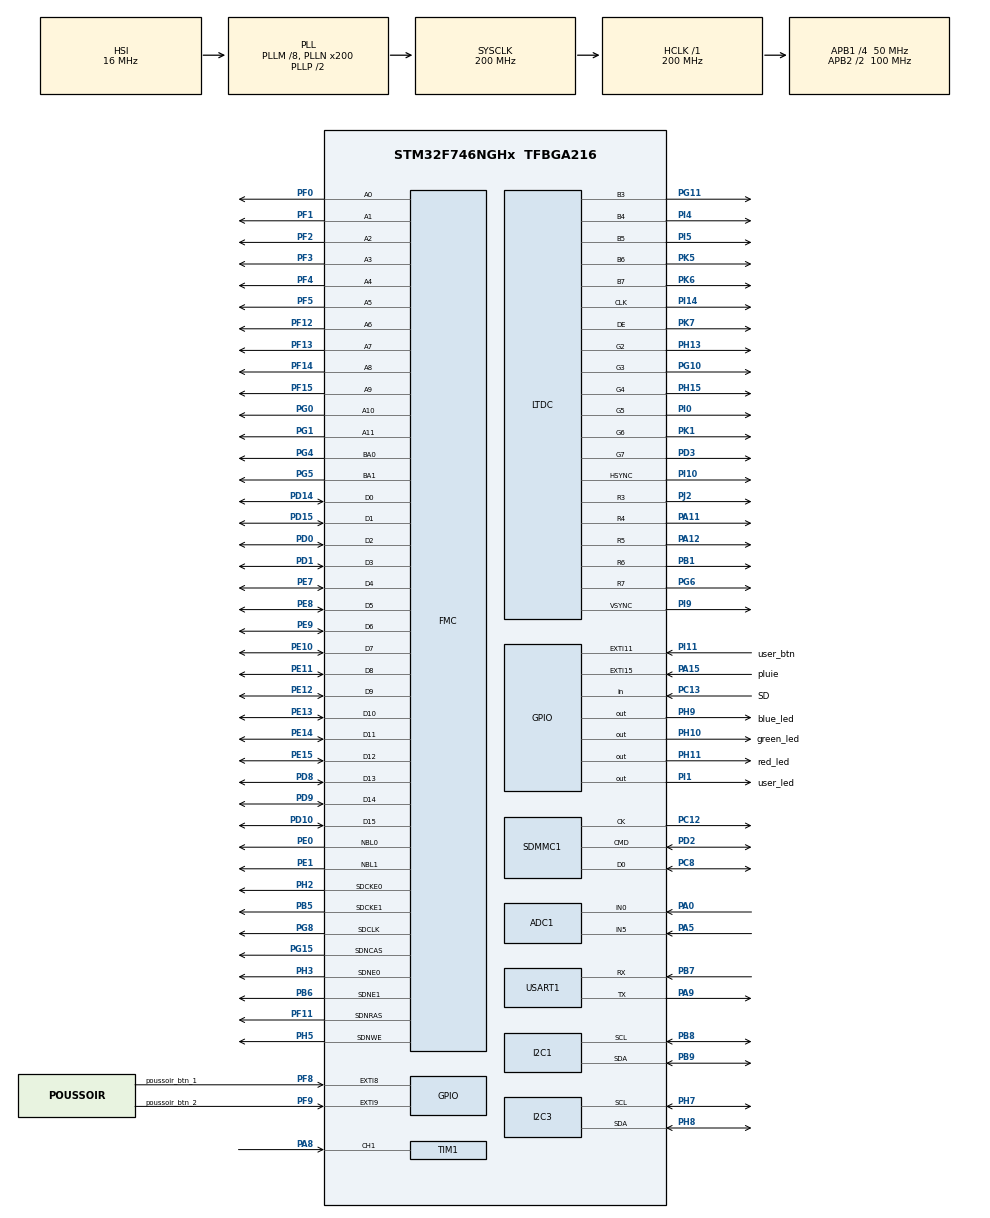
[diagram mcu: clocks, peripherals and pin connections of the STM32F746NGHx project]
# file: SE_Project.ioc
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ADC1.Channel-0\#ChannelRegularConversion=ADC_CHANNEL_5
ADC1.ContinuousConvMode=ENABLE
ADC1.NbrOfConversionFlag=1
ADC1.Rank-0\#ChannelRegularConversion=1
ADC1.SamplingTime-0\#ChannelRegularConversion=ADC_SAMPLETIME_3CYCLES
ADC1.master=1
ADC2.Channel-0\#ChannelRegularConversion=ADC_CHANNEL_0
ADC2.NbrOfConversionFlag=1
ADC2.Rank-0\#ChannelRegularConversion=1
ADC2.SamplingTime-0\#ChannelRegularConversion=ADC_SAMPLETIME_3CYCLES
Dma.Request0=SDMMC1_RX
Dma.Request1=SDMMC1_TX
Dma.SDMMC1_RX.0.Direction=DMA_PERIPH_TO_MEMORY
Dma.SDMMC1_RX.0.FIFOMode=DMA_FIFOMODE_ENABLE
Dma.SDMMC1_RX.0.FIFOThreshold=DMA_FIFO_THRESHOLD_FULL
Dma.SDMMC1_RX.0.Instance=DMA2_Stream3
Dma.SDMMC1_RX.0.MemBurst=DMA_MBURST_INC4
Dma.SDMMC1_RX.0.MemDataAlignment=DMA_MDATAALIGN_WORD
Dma.SDMMC1_RX.0.MemInc=DMA_MINC_ENABLE
Dma.SDMMC1_RX.0.Mode=DMA_PFCTRL
Dma.SDMMC1_RX.0.PeriphBurst=DMA_PBURST_INC4
Dma.SDMMC1_RX.0.PeriphDataAlignment=DMA_PDATAALIGN_WORD
Dma.SDMMC1_RX.0.PeriphInc=DMA_PINC_DISABLE
Dma.SDMMC1_RX.0.Priority=DMA_PRIORITY_LOW
Dma.SDMMC1_TX.1.Direction=DMA_MEMORY_TO_PERIPH
Dma.SDMMC1_TX.1.FIFOMode=DMA_FIFOMODE_ENABLE
Dma.SDMMC1_TX.1.FIFOThreshold=DMA_FIFO_THRESHOLD_FULL
Dma.SDMMC1_TX.1.Instance=DMA2_Stream6
Dma.SDMMC1_TX.1.MemBurst=DMA_MBURST_INC4
Dma.SDMMC1_TX.1.MemDataAlignment=DMA_MDATAALIGN_WORD
Dma.SDMMC1_TX.1.MemInc=DMA_MINC_ENABLE
Dma.SDMMC1_TX.1.Mode=DMA_PFCTRL
Dma.SDMMC1_TX.1.PeriphBurst=DMA_PBURST_INC4
Dma.SDMMC1_TX.1.PeriphDataAlignment=DMA_PDATAALIGN_WORD
Dma.SDMMC1_TX.1.PeriphInc=DMA_PINC_DISABLE
Dma.SDMMC1_TX.1.Priority=DMA_PRIORITY_LOW
FATFS.BSP.number=1
FATFS.USE_DMA_CODE_SD=1
FATFS0.BSP.STBoard=false
FATFS0.BSP.api=Unknown
FATFS0.BSP.instance=PC13
FATFS0.BSP.ip=GPIO
FATFS0.BSP.mode=Input
FATFS0.BSP.name=Detect_SDIO
FATFS0.BSP.solution=PC13
I2C1.Timing=0x00C0EAFF
I2C3.Timing=0x00C0EAFF
Mcu.Family=STM32F7
Mcu.Name=STM32F746NGHx
Mcu.Package=TFBGA216
NVIC.ADC_IRQn=true\:0\:0\:false\:false\:true\:true\:true\:true
NVIC.DMA2_Stream3_IRQn=true\:0\:0\:false\:false\:true\:false\:true\:true
NVIC.DMA2_Stream6_IRQn=true\:0\:0\:false\:false\:true\:false\:true\:true
NVIC.EXTI15_10_IRQn=true\:0\:0\:false\:false\:true\:true\:true\:true
NVIC.EXTI9_5_IRQn=true\:0\:0\:false\:false\:true\:true\:true\:true
NVIC.PVD_IRQn=true\:0\:0\:false\:false\:true\:true\:true\:true
NVIC.PriorityGroup=NVIC_PRIORITYGROUP_4
NVIC.RCC_IRQn=true\:0\:0\:false\:false\:true\:true\:false\:true
NVIC.SDMMC1_IRQn=true\:0\:0\:false\:false\:true\:true\:true\:true
NVIC.TIM1_CC_IRQn=true\:0\:0\:false\:false\:true\:true\:true\:true
NVIC.TIM2_IRQn=true\:0\:0\:false\:false\:true\:true\:true\:true
NVIC.TIM3_IRQn=true\:0\:0\:false\:false\:true\:true\:true\:true
NVIC.TIM4_IRQn=true\:0\:0\:false\:false\:true\:true\:true\:true
NVIC.TIM5_IRQn=true\:0\:0\:false\:false\:true\:true\:true\:true
NVIC.TIM7_IRQn=true\:0\:0\:false\:false\:true\:true\:true\:true
PA0/WKUP.Signal=ADCx_IN0
PA11.Mode=RGB565
PA11.Signal=LTDC_R4
PA12.Mode=RGB565
PA12.Signal=LTDC_R5
PA13.Mode=Serial_Wire
PA13.Signal=SYS_JTMS-SWDIO
PA14.Mode=Serial_Wire
PA14.Signal=SYS_JTCK-SWCLK
PA15.GPIO_Label=pluie
PA15.GPIO_ModeDefaultEXTI=GPIO_MODE_IT_FALLING
PA15.GPIO_PuPd=GPIO_PULLUP
PA15.Signal=GPXTI15
PA5.Signal=ADCx_IN5
PA8.GPIO_PuPd=GPIO_PULLUP
PA8.Signal=S_TIM1_CH1
PA9.Mode=Asynchronous
PA9.Signal=USART1_TX
PB1.Mode=RGB565
PB1.Signal=LTDC_R6
PB5.Mode=SdramChipSelect2_2
PB5.Signal=FMC_SDCKE1
PB6.Mode=SdramChipSelect2_2
PB6.Signal=FMC_SDNE1
PB7.Mode=Asynchronous
PB7.Signal=USART1_RX
PB8.Mode=I2C
PB8.Signal=I2C1_SCL
PB9.Mode=I2C
PB9.Signal=I2C1_SDA
PC12.Mode=SD_1_bit
PC12.Signal=SDMMC1_CK
PC13.GPIO_Label=SD
PC13.Signal=GPIO_Input
PC8.Mode=SD_1_bit
PC8.Signal=SDMMC1_D0
PD0.Signal=FMC_D2_DA2
PD1.Signal=FMC_D3_DA3
PD10.Signal=FMC_D15_DA15
PD14.Signal=FMC_D0_DA0
PD15.Signal=FMC_D1_DA1
PD2.Mode=SD_1_bit
PD2.Signal=SDMMC1_CMD
PD3.Mode=RGB565
PD3.Signal=LTDC_G7
PD8.Signal=FMC_D13_DA13
PD9.Signal=FMC_D14_DA14
PE0.Signal=FMC_NBL0
PE1.Signal=FMC_NBL1
PE10.Signal=FMC_D7_DA7
PE11.Signal=FMC_D8_DA8
PE12.Signal=FMC_D9_DA9
PE13.Signal=FMC_D10_DA10
PE14.Signal=FMC_D11_DA11
PE15.Signal=FMC_D12_DA12
PE7.Signal=FMC_D4_DA4
PE8.Signal=FMC_D5_DA5
PE9.Signal=FMC_D6_DA6
PF0.Signal=FMC_A0
PF1.Signal=FMC_A1
PF11.Signal=FMC_SDNRAS
PF12.Signal=FMC_A6
PF13.Signal=FMC_A7
PF14.Signal=FMC_A8
PF15.Signal=FMC_A9
PF2.Signal=FMC_A2
PF3.Signal=FMC_A3
PF4.Signal=FMC_A4
PF5.Signal=FMC_A5
PF8.GPIO_Label=poussoir_btn_1
PF8.Signal=GPXTI8
PF9.GPIO_Label=poussoir_btn_2
PF9.Signal=GPXTI9
PG0.Signal=FMC_A10
PG1.Signal=FMC_A11
PG10.Mode=RGB565
PG10.Signal=LTDC_G3
PG11.Mode=RGB565
PG11.Signal=LTDC_B3
PG15.Signal=FMC_SDNCAS
PG4.Signal=FMC_A14_BA0
PG5.Signal=FMC_A15_BA1
PG6.Mode=RGB565
PG6.Signal=LTDC_R7
PG8.Signal=FMC_SDCLK
PH0/OSC_IN.Mode=HSE-External-Oscillator
PH0/OSC_IN.Signal=RCC_OSC_IN
PH1/OSC_OUT.Mode=HSE-External-Oscillator
PH1/OSC_OUT.Signal=RCC_OSC_OUT
PH10.GPIO_Label=green_led
PH10.Signal=GPIO_Output
PH11.GPIO_Label=red_led
PH11.Signal=GPIO_Output
PH13.Mode=RGB565
PH13.Signal=LTDC_G2
PH15.Mode=RGB565
PH15.Signal=LTDC_G4
PH2.Mode=SdramChipSelect1_1
PH2.Signal=FMC_SDCKE0
PH3.Mode=SdramChipSelect1_1
PH3.Signal=FMC_SDNE0
PH5.Signal=FMC_SDNWE
PH7.Mode=I2C
PH7.Signal=I2C3_SCL
PH8.Mode=I2C
PH8.Signal=I2C3_SDA
PH9.GPIO_Label=blue_led
PH9.Signal=GPIO_Output
PI0.Mode=RGB565
PI0.Signal=LTDC_G5
PI1.GPIO_Label=user_led
PI1.Signal=GPIO_Output
PI10.Mode=RGB565
PI10.Signal=LTDC_HSYNC
PI11.GPIO_Label=user_btn
PI11.Signal=GPXTI11
PI14.Mode=RGB565
PI14.Signal=LTDC_CLK
PI4.Mode=RGB565
PI4.Signal=LTDC_B4
PI5.Mode=RGB565
PI5.Signal=LTDC_B5
PI9.Mode=RGB565
PI9.Signal=LTDC_VSYNC
PJ2.Mode=RGB565
PJ2.Signal=LTDC_R3
PK1.Mode=RGB565
PK1.Signal=LTDC_G6
PK5.Mode=RGB565
PK5.Signal=LTDC_B6
PK6.Mode=RGB565
PK6.Signal=LTDC_B7
PK7.Mode=RGB565
PK7.Signal=LTDC_DE
ProjectManager.HeapSize=0x200
ProjectManager.StackSize=0x400
ProjectManager.TargetToolchain=STM32CubeIDE
RCC.AHBFreq_Value=200000000
RCC.APB1CLKDivider=RCC_HCLK_DIV4
RCC.APB1Freq_Value=50000000
RCC.APB1TimFreq_Value=100000000
RCC.APB2CLKDivider=RCC_HCLK_DIV2
RCC.APB2Freq_Value=100000000
RCC.APB2TimFreq_Value=200000000
RCC.CortexFreq_Value=200000000
RCC.HCLKFreq_Value=200000000
RCC.HSE_VALUE=25000000
RCC.HSI_VALUE=16000000
RCC.LSE_VALUE=32768
RCC.PLLM=8
RCC.PLLN=200
RCC.PLLQ=8
RCC.PLLSAIN=50
RCC.PLLSourceVirtual=RCC_PLLSOURCE_HSI
RCC.SDMMCClockSelection=RCC_SDMMC1CLKSOURCE_CLK48
RCC.SYSCLKFreq_VALUE=200000000
RCC.SYSCLKSource=RCC_SYSCLKSOURCE_PLLCLK
RCC.USBFreq_Value=50000000
RCC.VCOOutputFreq_Value=400000000
SH.ADCx_IN0.0=ADC1_IN0,IN0
SH.ADCx_IN0.1=ADC2_IN0,IN0
SH.ADCx_IN5.0=ADC1_IN5,IN5
SH.FMC_A0.0=FMC_A0,12b-sda1
SH.FMC_A0.1=FMC_A0,12b-sda2
SH.FMC_A1.0=FMC_A1,12b-sda1
SH.FMC_A1.1=FMC_A1,12b-sda2
SH.FMC_A10.0=FMC_A10,12b-sda1
SH.FMC_A10.1=FMC_A10,12b-sda2
SH.FMC_A11.0=FMC_A11,12b-sda1
SH.FMC_A11.1=FMC_A11,12b-sda2
SH.FMC_A14_BA0.0=FMC_BA0,FourSdramBanks1
SH.FMC_A14_BA0.1=FMC_BA0,FourSdramBanks2
SH.FMC_A15_BA1.0=FMC_BA1,FourSdramBanks1
SH.FMC_A15_BA1.1=FMC_BA1,FourSdramBanks2
SH.FMC_A2.0=FMC_A2,12b-sda1
SH.FMC_A2.1=FMC_A2,12b-sda2
SH.FMC_A3.0=FMC_A3,12b-sda1
SH.FMC_A3.1=FMC_A3,12b-sda2
SH.FMC_A4.0=FMC_A4,12b-sda1
SH.FMC_A4.1=FMC_A4,12b-sda2
SH.FMC_A5.0=FMC_A5,12b-sda1
SH.FMC_A5.1=FMC_A5,12b-sda2
SH.FMC_A6.0=FMC_A6,12b-sda1
SH.FMC_A6.1=FMC_A6,12b-sda2
SH.FMC_A7.0=FMC_A7,12b-sda1
SH.FMC_A7.1=FMC_A7,12b-sda2
SH.FMC_A8.0=FMC_A8,12b-sda1
SH.FMC_A8.1=FMC_A8,12b-sda2
SH.FMC_A9.0=FMC_A9,12b-sda1
SH.FMC_A9.1=FMC_A9,12b-sda2
SH.FMC_D0_DA0.0=FMC_D0,sd-16b-d1
SH.FMC_D0_DA0.1=FMC_D0,sd-16b-d2
SH.FMC_D10_DA10.0=FMC_D10,sd-16b-d1
SH.FMC_D10_DA10.1=FMC_D10,sd-16b-d2
SH.FMC_D11_DA11.0=FMC_D11,sd-16b-d1
SH.FMC_D11_DA11.1=FMC_D11,sd-16b-d2
SH.FMC_D12_DA12.0=FMC_D12,sd-16b-d1
SH.FMC_D12_DA12.1=FMC_D12,sd-16b-d2
SH.FMC_D13_DA13.0=FMC_D13,sd-16b-d1
SH.FMC_D13_DA13.1=FMC_D13,sd-16b-d2
SH.FMC_D14_DA14.0=FMC_D14,sd-16b-d1
SH.FMC_D14_DA14.1=FMC_D14,sd-16b-d2
SH.FMC_D15_DA15.0=FMC_D15,sd-16b-d1
SH.FMC_D15_DA15.1=FMC_D15,sd-16b-d2
SH.FMC_D1_DA1.0=FMC_D1,sd-16b-d1
SH.FMC_D1_DA1.1=FMC_D1,sd-16b-d2
SH.FMC_D2_DA2.0=FMC_D2,sd-16b-d1
SH.FMC_D2_DA2.1=FMC_D2,sd-16b-d2
SH.FMC_D3_DA3.0=FMC_D3,sd-16b-d1
SH.FMC_D3_DA3.1=FMC_D3,sd-16b-d2
SH.FMC_D4_DA4.0=FMC_D4,sd-16b-d1
SH.FMC_D4_DA4.1=FMC_D4,sd-16b-d2
SH.FMC_D5_DA5.0=FMC_D5,sd-16b-d1
SH.FMC_D5_DA5.1=FMC_D5,sd-16b-d2
SH.FMC_D6_DA6.0=FMC_D6,sd-16b-d1
SH.FMC_D6_DA6.1=FMC_D6,sd-16b-d2
SH.FMC_D7_DA7.0=FMC_D7,sd-16b-d1
SH.FMC_D7_DA7.1=FMC_D7,sd-16b-d2
SH.FMC_D8_DA8.0=FMC_D8,sd-16b-d1
SH.FMC_D8_DA8.1=FMC_D8,sd-16b-d2
SH.FMC_D9_DA9.0=FMC_D9,sd-16b-d1
SH.FMC_D9_DA9.1=FMC_D9,sd-16b-d2
SH.FMC_NBL0.0=FMC_NBL0,Sd2ByteEnable1
SH.FMC_NBL0.1=FMC_NBL0,Sd2ByteEnable2
SH.FMC_NBL1.0=FMC_NBL1,Sd2ByteEnable1
SH.FMC_NBL1.1=FMC_NBL1,Sd2ByteEnable2
SH.FMC_SDCLK.0=FMC_SDCLK,12b-sda1
SH.FMC_SDCLK.1=FMC_SDCLK,12b-sda2
SH.FMC_SDNCAS.0=FMC_SDNCAS,12b-sda1
SH.FMC_SDNCAS.1=FMC_SDNCAS,12b-sda2
SH.FMC_SDNRAS.0=FMC_SDNRAS,12b-sda1
SH.FMC_SDNRAS.1=FMC_SDNRAS,12b-sda2
SH.FMC_SDNWE.0=FMC_SDNWE,12b-sda1
SH.FMC_SDNWE.1=FMC_SDNWE,12b-sda2
SH.S_TIM1_CH1.0=TIM1_CH1,Input_Capture1_from_TI1
TIM1.Channel-Input_Capture1_from_TI1=TIM_CHANNEL_1
TIM1.ICFilter_CH1=15
TIM1.Period=24999
TIM1.Prescaler=19999
TIM2.Period=35999999
TIM2.Prescaler=9999
TIM3.Period=499
TIM3.Prescaler=4999
TIM4.Period=59999
TIM4.Prescaler=49999
TIM5.Period=49999
TIM5.Prescaler=9999
TIM7.Period=999
TIM7.Prescaler=9999
USART1.VirtualMode-Asynchronous=VM_ASYNC
VP_DMA2D_VS_DMA2D.Mode=DMA2D_Activate
VP_FATFS_VS_SDIO.Mode=SDIO
VP_RTC_VS_RTC_Activate.Mode=RTC_Enabled
VP_RTC_VS_RTC_Calendar.Mode=RTC_Calendar
VP_TIM2_VS_ClockSourceITR.Mode=TriggerSource_ITR0
VP_TIM2_VS_ControllerModeReset.Mode=Reset Mode
VP_TIM3_VS_ClockSourceITR.Mode=TriggerSource_ITR0
VP_TIM3_VS_ControllerModeReset.Mode=Reset Mode
VP_TIM4_VS_ClockSourceITR.Mode=TriggerSource_ITR0
VP_TIM4_VS_ControllerModeReset.Mode=Reset Mode
VP_TIM5_VS_ClockSourceITR.Mode=TriggerSource_ITR0
VP_TIM5_VS_ControllerModeReset.Mode=Reset Mode
VP_TIM7_VS_ClockSourceINT.Mode=Enable_Timer
board=STM32F746G-DISCO

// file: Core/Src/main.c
/* USER CODE BEGIN Header */
/**
  ******************************************************************************
  * @file           : main.c
  * @brief          : Main program body
  ******************************************************************************
  * @attention
  *
  * Copyright (c) 2024 STMicroelectronics.
  * All rights reserved.
  *
  * This software is licensed under terms that can be found in the LICENSE file
  * in the root directory of this software component.
  * If no LICENSE file comes with this software, it is provided AS-IS.
  *
  ******************************************************************************
  */
/* USER CODE END Header */
#include "main.h"
#include "adc.h"
#include "dma.h"
#include "dma2d.h"
#include "fatfs.h"
#include "i2c.h"
#include "ltdc.h"
#include "rtc.h"
#include "sdmmc.h"
#include "tim.h"
#include "usart.h"
#include "gpio.h"
#include "fmc.h"

/* USER CODE BEGIN Includes */
//Ecran include
#include "stm32746g_discovery.h"
#include "stm32746g_discovery_sdram.h"
#include "stm32746g_discovery_lcd.h"
#include "stm32746g_discovery_ts.h"
//
#include "stm32f7xx_hal.h"

#include <stdio.h>
#include <string.h>

#include "humidity.h"
#include "pression.h"
#include "pluviometre.h"
#include "display_reg.h"

/* USER CODE END Includes */

/* USER CODE BEGIN PD */
#define BLOCK_WIDTH 200
#define BLOCK_HEIGHT 100
#define BLOCK_PADDING 20

#define BUTTON_WIDTH_fl 100
#define BUTTON_HEIGHT_fl 50

/* USER CODE END PD */

/* USER CODE BEGIN PV */
/* Private variables ---------------------------------------------------------*/

/*
 * -----------------------------------------------------------------------------
 * Pour ce code on a fait des fichiers.h et fichiers.c pour ne pas
 * surcharger notre main.c
 * ------------------------------------------------------------------------------
 * */

extern volatile float pressure_hPa; //Variable contenant la pression ATMOS
extern volatile hum_temp_t grandeur; //Struct définis dans humidity.h contenant Temp et hum

//Variables utilise pour les interruptions
volatile uint8_t  action = 1, Flag_tim4 = 0, Flag_tim7 = 0, Flag_btn = 0, Flag_tim2 = 0,Flag_tim5=0;

/*Variables pour gérer respectivement:
 * action : 1 -> état acquisition RGB Vert
 * action : 0 -> Etat ecran veille RGB Rouge
 * action : -1 -> Etat save card SD RGB Bleu
 *
 *page = 0 : écran acceuil
 *page = 1 : écran capteurs arduino
 *page = 2 : écran pluviometre */

uint8_t    page = 0;

uint8_t workBuffer[_MAX_SS];
float tab_temp[2000], tab_hum[2000], tab_pluie[2000], tab_speed[2000];// a remplacer par les valeur des capteurs
extern volatile hum_temp_t grandeur;
uint8_t ac = 0;
extern volatile float qte_pluie, speed_kmh;

extern TIM_HandleTypeDef htim4;
extern TIM_HandleTypeDef htim7;
extern TIM_HandleTypeDef htim3;
extern TIM_HandleTypeDef htim2;

/* USER CODE END PV */

void SystemClock_Config(void);
/* USER CODE BEGIN PFP */
#define PUTCHAR_PROTOTYPE int __io_putchar(int ch)

//Gère la carte SD
void register_SD_CARD(float *array,float *array1,float *array2,float *array3, int size);
void detect_pluie();

//Remet le compteur du timer à 0, c'est pour gérer le timer qui éteint l'écran
void start_again_timer(TIM_HandleTypeDef htim);

/* USER CODE END PFP */

int main(void)
{

  /* MCU Configuration--------------------------------------------------------*/

  /* Reset of all peripherals, Initializes the Flash interface and the Systick. */
  HAL_Init();

  /* Configure the system clock */
  SystemClock_Config();

  /* Initialize all configured peripherals */
  MX_GPIO_Init();
  MX_DMA_Init();
  MX_DMA2D_Init();
  MX_FMC_Init();
  MX_I2C1_Init();
  MX_I2C3_Init();
  MX_LTDC_Init();
  MX_TIM3_Init();
  MX_USART1_UART_Init();
  MX_TIM4_Init();
  MX_TIM2_Init();
  MX_SDMMC1_SD_Init();
  MX_FATFS_Init();
  MX_ADC1_Init();
  MX_RTC_Init();
  MX_TIM1_Init();
  MX_TIM7_Init();
  MX_TIM5_Init();
  MX_ADC2_Init();
  /* USER CODE BEGIN 2 */

  HAL_Init();

  //On utilialise l'écran et le touchscreen
  BSP_LCD_Init();
  BSP_TS_Init(480, 272);
  //Ecran ephemère qui affiche juste le logo
  ephemere_screen();
  HAL_Delay(5000);

  /*Alumé juste le timer 3 pour gérer le touchscreen */
  HAL_TIM_Base_Init(&htim3);
  HAL_TIM_Base_Start_IT(&htim3);

  //Page d'acceuil pour choisir le temps d'acquisition
	BSP_LCD_LayerDefaultInit(LTDC_ACTIVE_LAYER, SDRAM_DEVICE_ADDR);
	BSP_LCD_SetLayerVisible(LTDC_ACTIVE_LAYER, ENABLE);
	BSP_LCD_SetFont(&LCD_DEFAULT_FONT);
	BSP_LCD_SelectLayer(LTDC_ACTIVE_LAYER);
	BSP_LCD_Clear(LCD_COLOR_WHITE);
	Home();
  while(page == 0); //Tant qu'on pas choisit le temps on reste à Home

  BSP_LCD_Clear(LCD_COLOR_WHITE);

  if(start_sensor_hts221()== -1) printf("Device for sensor hts221 not found!");
  if(start_sensor_lps22hh() == -1) printf("Device for sensor lps22hh not found!");

   //Affiche page 1
    BSP_LCD_Init();
    BSP_LCD_LayerDefaultInit(LTDC_ACTIVE_LAYER, SDRAM_DEVICE_ADDR);
    BSP_LCD_SelectLayer(LTDC_ACTIVE_LAYER);
    show_sensors();

  /* USER CODE END 2 */

  /* Infinite loop */
  /* USER CODE BEGIN WHILE */
  HAL_TIM_Base_Init(&htim5) ;
  HAL_TIM_Base_Init(&htim4) ;
  HAL_TIM_Base_Init(&htim2) ;
  HAL_TIM_Base_Init(&htim7) ;

   HAL_TIM_IC_Start_IT(&htim1, TIM_CHANNEL_1);

   HAL_TIM_Base_Start_IT(&htim4);
   HAL_TIM_Base_Start_IT(&htim7);
   HAL_TIM_Base_Start_IT(&htim2);
   HAL_TIM_Base_Start_IT(&htim5);

   HAL_NVIC_SetPriority(TIM2_IRQn, 1, 0);
   HAL_NVIC_SetPriority(TIM4_IRQn, 2, 0);
   HAL_NVIC_SetPriority(TIM7_IRQn, 1, 0);

  //RGB Vert pour symboliser l'acquisiiton
  HAL_GPIO_WritePin(green_led_GPIO_Port, green_led_Pin, GPIO_PIN_RESET);

  //Routine de l'app
  while (1)
  {
	  if(Flag_tim5 == 1){
		  if(page == 1)show_sensors();
		  else if(page == 2) show_rain();

		  if(ac<=5000){//Si le tableau n'est pas encore pleine on remplit
			  tab_temp[ac] = grandeur.temp;
			  tab_hum[ac] = grandeur.hum;
			  tab_pluie[ac] = qte_pluie ;
			  tab_speed[ac] = speed_kmh;
			  ac++;
		  }
		  else{//S'il est plein, on save et on remet le tableau au debut
			  //register_SD_CARD(tab_temp, tab_hum, tab_pluie, tab_speed,  ac);
			  ac = 0;
		  }
		  Flag_tim5 = 0;
	  }
	  else if(Flag_tim4 == 1){ // Eteindre l'écran quand cette interruption est lévée
		  BSP_LCD_DisplayOff();
		  action = 0;

		  Flag_tim4 =  0;
	  }
	  else if(Flag_tim2 == 1){
		  //Enregistrer toutes les 5min dans la carte SD

		  register_SD_CARD(tab_temp, tab_hum, tab_pluie, tab_speed,  ac);
		  Flag_tim2 = 0;
		  //On remet le tableau vide pour remplir
		  ac = 0;
	  }
	  else if(Flag_tim7 == 1){
		  //Vérifié l'action ou l'etat du STM pour choisir le RGB correspondent
		  if(action){
			  HAL_GPIO_WritePin(red_led_GPIO_Port, red_led_Pin, 0);
			  HAL_GPIO_TogglePin(green_led_GPIO_Port, green_led_Pin);
		  }
		  else{
			  HAL_GPIO_WritePin(green_led_GPIO_Port, green_led_Pin, 0);
			  HAL_GPIO_TogglePin(red_led_GPIO_Port, red_led_Pin);
		  }
		  Flag_tim7 = 0;
	  }
	  else if(Flag_btn == 1){
		  /*Quand appuis sur le button User, remettre
		   * le compteur du timer 2 qui compte 30s pour l'écran à 0
		   */
		  start_again_timer(htim2);
		  //Si on touche btn user, on reallume l'écran LCD
		  BSP_LCD_DisplayOn();

		  //On remet l'état en acquisiiton
		  action = 1;
		  Flag_btn = 0;
	  }
	  else{
		  //Gestion des interruptions
		  HAL_SuspendTick();
		  HAL_PWR_EnterSLEEPMode(PWR_MAINREGULATOR_ON, PWR_SLEEPENTRY_WFE);
		  HAL_ResumeTick();
	  }
    /* USER CODE END WHILE */

  }
}

void SystemClock_Config(void)
{
  RCC_OscInitTypeDef RCC_OscInitStruct = {0};
  RCC_ClkInitTypeDef RCC_ClkInitStruct = {0};

  /** Configure the main internal regulator output voltage
  */
  __HAL_RCC_PWR_CLK_ENABLE();
  __HAL_PWR_VOLTAGESCALING_CONFIG(PWR_REGULATOR_VOLTAGE_SCALE1);

  /** Initializes the RCC Oscillators according to the specified parameters
  * in the RCC_OscInitTypeDef structure.
  */
  RCC_OscInitStruct.OscillatorType = RCC_OSCILLATORTYPE_HSI|RCC_OSCILLATORTYPE_LSI;
  RCC_OscInitStruct.HSIState = RCC_HSI_ON;
  RCC_OscInitStruct.HSICalibrationValue = RCC_HSICALIBRATION_DEFAULT;
  RCC_OscInitStruct.LSIState = RCC_LSI_ON;
  RCC_OscInitStruct.PLL.PLLState = RCC_PLL_ON;
  RCC_OscInitStruct.PLL.PLLSource = RCC_PLLSOURCE_HSI;
  RCC_OscInitStruct.PLL.PLLM = 8;
  RCC_OscInitStruct.PLL.PLLN = 200;
  RCC_OscInitStruct.PLL.PLLP = RCC_PLLP_DIV2;
  RCC_OscInitStruct.PLL.PLLQ = 8;
  if (HAL_RCC_OscConfig(&RCC_OscInitStruct) != HAL_OK)
  {
    Error_Handler();
  }

  /** Activate the Over-Drive mode
  */
  if (HAL_PWREx_EnableOverDrive() != HAL_OK)
  {
    Error_Handler();
  }

  /** Initializes the CPU, AHB and APB buses clocks
  */
  RCC_ClkInitStruct.ClockType = RCC_CLOCKTYPE_HCLK|RCC_CLOCKTYPE_SYSCLK
                              |RCC_CLOCKTYPE_PCLK1|RCC_CLOCKTYPE_PCLK2;
  RCC_ClkInitStruct.SYSCLKSource = RCC_SYSCLKSOURCE_PLLCLK;
  RCC_ClkInitStruct.AHBCLKDivider = RCC_SYSCLK_DIV1;
  RCC_ClkInitStruct.APB1CLKDivider = RCC_HCLK_DIV4;
  RCC_ClkInitStruct.APB2CLKDivider = RCC_HCLK_DIV2;

  if (HAL_RCC_ClockConfig(&RCC_ClkInitStruct, FLASH_LATENCY_6) != HAL_OK)
  {
    Error_Handler();
  }
}

/* USER CODE BEGIN 4 */

PUTCHAR_PROTOTYPE
{
  /* Place your implementation of fputc here */
  /* e.g. write a character to the USART1 and Loop until the end of transmission */
  HAL_UART_Transmit(&huart1, (uint8_t *)&ch, 1, 0xFFFF);

  return ch;
}

void start_again_timer(TIM_HandleTypeDef htim){
	//Fonction mis à 0 le compteur du timer
	HAL_TIM_Base_Stop(&htim2);
	__HAL_TIM_SET_COUNTER(&htim2, 0);
	HAL_TIM_Base_Start(&htim2);
}
void register_SD_CARD(float *array,float *array1,float *array2,float *array3, int size) {
    /*##-1- Link the micro SD disk I/O driver ##################################*/
    // if(FATFS_LinkDriver(&SD_Driver, SDPath) == 0)
    // {

    /*##-2- Register the file system object to the FatFs module ##############*/
    if (f_mount(&SDFatFS, (TCHAR const *)SDPath, 0) != FR_OK) {
        /* FatFs Initialization Error */
        Error_Handler();
    } else {
        /*##-3- Create a FAT file system (format) on the logical drive #########*/
        /* WARNING: Formatting the uSD card will delete all content on the device */
    	printf("1er reussi\r\n");
        if (f_mkfs((TCHAR const *)SDPath, FM_ANY, 0, workBuffer, sizeof(workBuffer)) != FR_OK) {
            /* FatFs Format Error */
            Error_Handler();
        } else {
            /*##-4- Create and Open a new text file object with write access #####*/
            if (f_open(&SDFile, "data.csv", FA_OPEN_ALWAYS | FA_WRITE) != FR_OK) {
                /* 'test.csv' file Open for write Error */
                Error_Handler();
            } else {
                /*##-5- Write array data along with RTC time to the CSV file #####*/
                char buffer[100];
                UINT byteswritten;
                FRESULT res;

                /* Write CSV header */
                snprintf(buffer, sizeof(buffer), "Year/Month/Day;Hour:Minute:Second;Temp;Hum;Pluie;Speed\n");
                res = f_write(&SDFile, buffer, strlen(buffer), (void *)&byteswritten);
                if ((byteswritten == 0) || (res != FR_OK)) {
                    Error_Handler();
                }
                for (int i = 0; i < size; i++) {
                    /* Fetch RTC time */
                    RTC_TimeTypeDef sTime;
                    RTC_DateTypeDef sDate;

                    HAL_RTC_GetTime(&hrtc, &sTime, RTC_FORMAT_BIN);
                    HAL_RTC_GetDate(&hrtc, &sDate, RTC_FORMAT_BIN);

                    /* Format data into CSV row */
                    snprintf(buffer, sizeof(buffer), "%04d/%02d/%02d;%02d:%02d:%02d;%f;%f;%f;%f\n",
                             2000 + sDate.Year, sDate.Month, sDate.Date, sTime.Hours, sTime.Minutes, sTime.Seconds, array[i], array1[i], array2[i], array3[i]);

                    res = f_write(&SDFile, buffer, strlen(buffer), (void *)&byteswritten);

                    if ((byteswritten == 0) || (res != FR_OK)) {
                        /* 'test.csv' file Write or EOF Error */
                        Error_Handler();
                        break;
                    }
                }

                /*##-6- Close the open text file #################################*/
                f_close(&SDFile);
            }
        }
    }

    FATFS_UnLinkDriver(SDPath);
}

void stop_Mode(){
	HAL_GPIO_WritePin(user_led_GPIO_Port, user_led_Pin, GPIO_PIN_RESET);
	HAL_GPIO_WritePin(green_led_GPIO_Port, green_led_Pin, GPIO_PIN_RESET);
	HAL_GPIO_WritePin(blue_led_GPIO_Port, blue_led_Pin, GPIO_PIN_RESET);
	HAL_GPIO_WritePin(red_led_GPIO_Port, red_led_Pin, GPIO_PIN_RESET);
}

/* USER CODE END 4 */

void Error_Handler(void)
{
  __disable_irq();
  while (1)
  {
  }
}
